VERSION ""

NS_ :

BS_:

BU_:

BO_ 3221225472 VECTOR__INDEPENDENT_SIG_MSG: 0 Vector__XXX
 SG_ PT_PumpStateByDrv_AAAA : 0|3@1- (1,0) [0|0] "" Vector__XXX

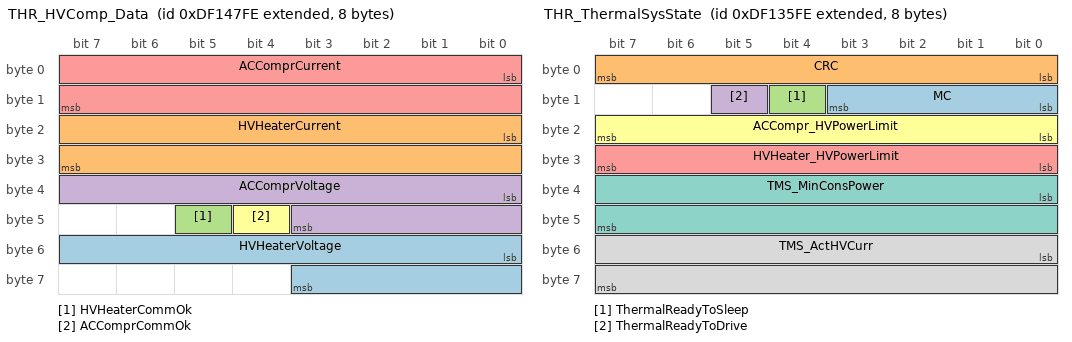
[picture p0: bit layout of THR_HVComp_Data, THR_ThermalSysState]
BO_ 2381400062 THR_HVComp_Data: 8 Vector__XXX
 SG_ HVHeaterVoltage : 48|12@1+ (0.2,0) [0|819] "V" Vector__XXX
 SG_ HVHeaterCurrent : 16|16@1+ (0.05,0) [0|3276.75] "A" Vector__XXX
 SG_ HVHeaterCommOk : 45|1@1+ (1,0) [0|1] "" Vector__XXX
 SG_ ACComprVoltage : 32|12@1+ (0.2,0) [0|819] "V" Vector__XXX
 SG_ ACComprCurrent : 0|16@1+ (0.05,0) [0|3276.75] "A" Vector__XXX
 SG_ ACComprCommOk : 44|1@1+ (1,0) [0|1] "" Vector__XXX

BO_ 2381395454 THR_ThermalSysState: 8 Vector__XXX
 SG_ MC : 8|4@1+ (1,0) [0|0] "" Vector__XXX
 SG_ CRC : 0|8@1+ (1,0) [0|0] "" Vector__XXX
 SG_ ThermalReadyToSleep : 12|1@1+ (1,0) [0|1] "" Vector__XXX
 SG_ ThermalReadyToDrive : 13|1@1+ (1,0) [0|1] "" Vector__XXX
 SG_ HVHeater_HVPowerLimit : 24|8@1+ (0.1,0) [0|25.5] "kW" Vector__XXX
 SG_ ACCompr_HVPowerLimit : 16|8@1+ (0.1,0) [0|25.5] "kW" Vector__XXX
 SG_ TMS_MinConsPower : 32|16@1+ (0.1,0) [0|6553.5] "kW" Vector__XXX
 SG_ TMS_ActHVCurr : 48|16@1+ (0.05,0) [0|3276.75] "A" Vector__XXX

BO_ 2382241790 Reserved1: 8 Vector__XXX

BO_ 2382241278 Reserved2: 8 Vector__XXX

CM_ "$File: //depot/auto/dbc/Software_Modules/Thermal_System/Thermal/0.2.0.0/Thermal.dbc $
$Change: 215790 $
$DateTime: 2024/08/14 11:07:50 $
$Revision: #1 $";
CM_ BO_ 3221225472 "This is a message for not used signals, created by Vector CANdb++ DBC OLE DB Provider.";
BA_DEF_ SG_  "SigType" ENUM  "Default","Range","RangeSigned","ASCII","Discrete","Control","ReferencePGN","DTC","StringDelimiter","StringLength","StringLengthControl","MessageCounter","MessageChecksum";
BA_DEF_ SG_  "GenSigEVName" STRING ;
BA_DEF_ SG_  "GenSigILSupport" ENUM  "No","Yes";
BA_DEF_ SG_  "GenSigSendType" ENUM  "Cyclic","OnWrite","OnWriteWithRepetition","OnChange","OnChangeWithRepetition","IfActive","IfActiveWithRepetition","NoSigSendType";
BA_DEF_ BO_  "GenMsgILSupport" ENUM  "No","Yes";
BA_DEF_ BU_  "NmStationAddress" INT 0 255;
BA_DEF_ BO_  "GenMsgSendType" ENUM  "cyclic","NotUsed","IfActive","NotUsed","NotUsed","NotUsed","NotUsed","NotUsed","noMsgSendType";
BA_DEF_ BO_  "GenMsgRequestable" INT 0 1;
BA_DEF_ BO_  "GenMsgCycleTime" INT 0 3600000;
BA_DEF_ BO_  "Producer" STRING ;
BA_DEF_  "DBName" STRING ;
BA_DEF_  "BusType" STRING ;
BA_DEF_  "ProtocolType" STRING ;
BA_DEF_ BO_  "VFrameFormat" ENUM  "StandardCAN","ExtendedCAN","reserved","J1939PG";
BA_DEF_DEF_  "SigType" "Default";
BA_DEF_DEF_  "GenSigEVName" "Env@Nodename_@Signame";
BA_DEF_DEF_  "GenSigILSupport" "Yes";
BA_DEF_DEF_  "GenSigSendType" "NoSigSendType";
BA_DEF_DEF_  "GenMsgILSupport" "Yes";
BA_DEF_DEF_  "NmStationAddress" 254;
BA_DEF_DEF_  "GenMsgSendType" "noMsgSendType";
BA_DEF_DEF_  "GenMsgRequestable" 1;
BA_DEF_DEF_  "GenMsgCycleTime" 0;
BA_DEF_DEF_  "Producer" "TMS";
BA_DEF_DEF_  "DBName" "Thermal";
BA_DEF_DEF_  "BusType" "CAN";
BA_DEF_DEF_  "ProtocolType" "J1939";
BA_DEF_DEF_  "VFrameFormat" "J1939PG";
BA_ "GenMsgSendType" BO_ 2381400062 0;
BA_ "GenMsgCycleTime" BO_ 2381400062 100;
BA_ "GenMsgSendType" BO_ 2381395454 0;
BA_ "GenMsgCycleTime" BO_ 2381395454 500;
BA_ "GenMsgSendType" BO_ 2382241790 0;
BA_ "GenMsgCycleTime" BO_ 2382241790 500;
BA_ "GenMsgSendType" BO_ 2382241278 0;
BA_ "GenMsgCycleTime" BO_ 2382241278 500;
